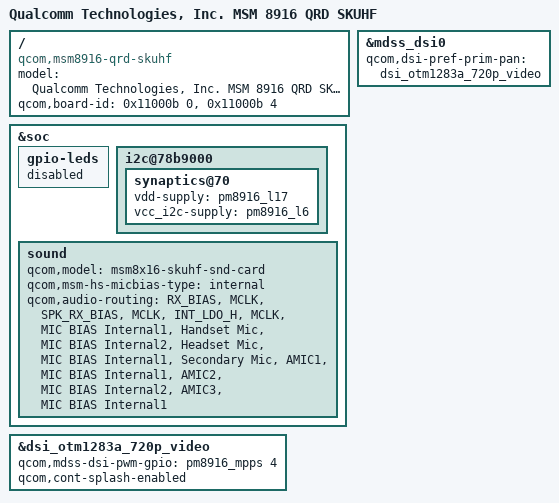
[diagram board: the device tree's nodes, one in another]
/* Copyright (c) 2014, The Linux Foundation. All rights reserved.
 *
 * This program is free software; you can redistribute it and/or modify
 * it under the terms of the GNU General Public License version 2 and
 * only version 2 as published by the Free Software Foundation.
 *
 * This program is distributed in the hope that it will be useful,
 * but WITHOUT ANY WARRANTY; without even the implied warranty of
 * MERCHANTABILITY or FITNESS FOR A PARTICULAR PURPOSE.  See the
 * GNU General Public License for more details.
 */

/dts-v1/;

#include "msm8916-qrd-skuh.dtsi"
#include "msm8916-memory.dtsi"

/ {
	model = "Qualcomm Technologies, Inc. MSM 8916 QRD SKUHF";
	compatible = "qcom,msm8916-qrd-skuhf", "qcom,msm8916-qrd", "qcom,msm8916", "qcom,qrd";
	qcom,board-id = <0x11000b 0> , <0x11000b 4>;
};

&soc {
	gpio-leds {
		status = "disabled";
	};

	i2c@78b9000 { /* BLSP1 QUP5 */
		synaptics@70 {
			vdd-supply = <&pm8916_l17>;
			vcc_i2c-supply = <&pm8916_l6>;
		};
	};

	sound {
		qcom,model = "msm8x16-skuhf-snd-card";
		qcom,msm-hs-micbias-type = "internal";
		qcom,audio-routing =
			"RX_BIAS", "MCLK",
			"SPK_RX_BIAS", "MCLK",
			"INT_LDO_H", "MCLK",
			"MIC BIAS Internal1", "Handset Mic",
			"MIC BIAS Internal2", "Headset Mic",
			"MIC BIAS Internal1", "Secondary Mic",
			"AMIC1", "MIC BIAS Internal1",
			"AMIC2", "MIC BIAS Internal2",
			"AMIC3", "MIC BIAS Internal1";
	};
};

#include "dsi-panel-otm1283a-720p-video.dtsi"

&dsi_otm1283a_720p_video {
	qcom,mdss-dsi-pwm-gpio = <&pm8916_mpps 4 0>;
	qcom,cont-splash-enabled;
};

&mdss_dsi0 {
	qcom,dsi-pref-prim-pan = <&dsi_otm1283a_720p_video>;
};
